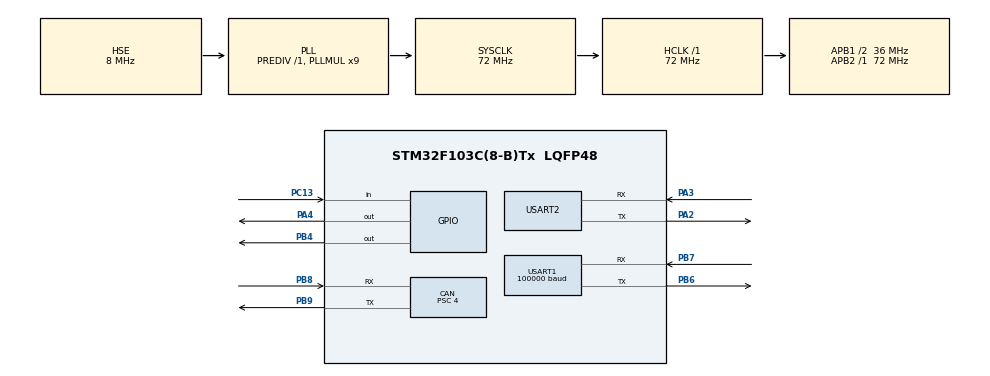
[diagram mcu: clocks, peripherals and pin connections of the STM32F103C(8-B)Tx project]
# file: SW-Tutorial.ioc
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CAN.BS1=CAN_BS1_6TQ
CAN.BS2=CAN_BS2_2TQ
CAN.CalculateBaudRate=1000000
CAN.CalculateTimeBit=1000
CAN.CalculateTimeQuantum=111.11111111111111
CAN.Mode=CAN_MODE_NORMAL
CAN.Prescaler=4
Dma.Request0=USART1_RX
Dma.USART1_RX.0.Direction=DMA_PERIPH_TO_MEMORY
Dma.USART1_RX.0.Instance=DMA1_Channel5
Dma.USART1_RX.0.MemDataAlignment=DMA_MDATAALIGN_BYTE
Dma.USART1_RX.0.MemInc=DMA_MINC_ENABLE
Dma.USART1_RX.0.Mode=DMA_NORMAL
Dma.USART1_RX.0.PeriphDataAlignment=DMA_PDATAALIGN_BYTE
Dma.USART1_RX.0.PeriphInc=DMA_PINC_DISABLE
Dma.USART1_RX.0.Priority=DMA_PRIORITY_VERY_HIGH
FREERTOS.Tasks01=defaultTask,24,128,StartDefaultTask,Default,NULL,Dynamic,NULL,NULL
Mcu.Family=STM32F1
Mcu.Name=STM32F103C(8-B)Tx
Mcu.Package=LQFP48
NVIC.DMA1_Channel5_IRQn=true\:5\:0\:false\:false\:true\:true\:false\:true\:true
NVIC.PriorityGroup=NVIC_PRIORITYGROUP_4
NVIC.TIM1_UP_IRQn=true\:15\:0\:false\:false\:true\:false\:false\:true\:true
NVIC.TimeBase=TIM1_UP_IRQn
NVIC.TimeBaseIP=TIM1
PA13.Mode=Serial_Wire
PA13.Signal=SYS_JTMS-SWDIO
PA14.Mode=Serial_Wire
PA14.Signal=SYS_JTCK-SWCLK
PA2.Mode=Asynchronous
PA2.Signal=USART2_TX
PA3.Mode=Asynchronous
PA3.Signal=USART2_RX
PA4.Signal=GPIO_Output
PB4.Signal=GPIO_Output
PB6.Mode=Asynchronous
PB6.Signal=USART1_TX
PB7.Mode=Asynchronous
PB7.Signal=USART1_RX
PB8.GPIO_PuPd=GPIO_PULLUP
PB8.Mode=CAN_Activate
PB8.Signal=CAN_RX
PB9.Mode=CAN_Activate
PB9.Signal=CAN_TX
PC13-TAMPER-RTC.Signal=GPIO_Input
PD0-OSC_IN.Mode=HSE-External-Oscillator
PD0-OSC_IN.Signal=RCC_OSC_IN
PD1-OSC_OUT.Mode=HSE-External-Oscillator
PD1-OSC_OUT.Signal=RCC_OSC_OUT
ProjectManager.HeapSize=0x200
ProjectManager.StackSize=0x400
ProjectManager.TargetToolchain=Makefile
RCC.AHBFreq_Value=72000000
RCC.APB1CLKDivider=RCC_HCLK_DIV2
RCC.APB1Freq_Value=36000000
RCC.APB1TimFreq_Value=72000000
RCC.APB2Freq_Value=72000000
RCC.APB2TimFreq_Value=72000000
RCC.HCLKFreq_Value=72000000
RCC.PLLMUL=RCC_PLL_MUL9
RCC.PLLSourceVirtual=RCC_PLLSOURCE_HSE
RCC.SYSCLKFreq_VALUE=72000000
RCC.SYSCLKSource=RCC_SYSCLKSOURCE_PLLCLK
RCC.USBFreq_Value=72000000
USART1.BaudRate=100000
USART1.Mode=MODE_RX
USART1.Parity=PARITY_EVEN
USART1.VirtualMode=VM_ASYNC
USART1.WordLength=WORDLENGTH_9B
USART2.Parity=PARITY_EVEN
USART2.VirtualMode=VM_ASYNC
USART2.WordLength=WORDLENGTH_9B
VP_FREERTOS_VS_CMSIS_V2.Mode=CMSIS_V2
VP_SYS_VS_tim1.Mode=TIM1
board=custom

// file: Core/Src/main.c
/* USER CODE BEGIN Header */
/**
 ******************************************************************************
 * @file           : main.c
 * @brief          : Main program body
 ******************************************************************************
 * @attention
 *
 * Copyright (c) 2022 STMicroelectronics.
 * All rights reserved.
 *
 * This software is licensed under terms that can be found in the LICENSE file
 * in the root directory of this software component.
 * If no LICENSE file comes with this software, it is provided AS-IS.
 *
 ******************************************************************************
 */
/* USER CODE END Header */
#include "main.h"
#include "cmsis_os.h"
#include "can.h"
#include "dma.h"
#include "usart.h"
#include "gpio.h"

/* USER CODE BEGIN Includes */
// #include "DR16.h"
#include "Motor.h"
/* USER CODE END Includes */

void SystemClock_Config(void);
void MX_FREERTOS_Init(void);

/* USER CODE BEGIN 0 */
extern void startUserTask();
/* USER CODE END 0 */

int main(void)
{

  /* MCU Configuration--------------------------------------------------------*/

  /* Reset of all peripherals, Initializes the Flash interface and the Systick. */
  HAL_Init();

  /* Configure the system clock */
  SystemClock_Config();

  /* Initialize all configured peripherals */
  MX_GPIO_Init();
  MX_DMA_Init();
  MX_CAN_Init();
  MX_USART1_UART_Init();
  MX_USART2_UART_Init();

  /* Init scheduler */
  osKernelInitialize();  /* Call init function for freertos objects (in freertos.c) */
  MX_FREERTOS_Init();

  /* Start scheduler */
  osKernelStart();

  /* We should never get here as control is now taken by the scheduler */
  /* Infinite loop */
  while (1)
  {

  }
}

void SystemClock_Config(void)
{
  RCC_OscInitTypeDef RCC_OscInitStruct = {0};
  RCC_ClkInitTypeDef RCC_ClkInitStruct = {0};

  /** Initializes the RCC Oscillators according to the specified parameters
  * in the RCC_OscInitTypeDef structure.
  */
  RCC_OscInitStruct.OscillatorType = RCC_OSCILLATORTYPE_HSE;
  RCC_OscInitStruct.HSEState = RCC_HSE_ON;
  RCC_OscInitStruct.HSEPredivValue = RCC_HSE_PREDIV_DIV1;
  RCC_OscInitStruct.HSIState = RCC_HSI_ON;
  RCC_OscInitStruct.PLL.PLLState = RCC_PLL_ON;
  RCC_OscInitStruct.PLL.PLLSource = RCC_PLLSOURCE_HSE;
  RCC_OscInitStruct.PLL.PLLMUL = RCC_PLL_MUL9;
  if (HAL_RCC_OscConfig(&RCC_OscInitStruct) != HAL_OK)
  {
    Error_Handler();
  }

  /** Initializes the CPU, AHB and APB buses clocks
  */
  RCC_ClkInitStruct.ClockType = RCC_CLOCKTYPE_HCLK|RCC_CLOCKTYPE_SYSCLK
                              |RCC_CLOCKTYPE_PCLK1|RCC_CLOCKTYPE_PCLK2;
  RCC_ClkInitStruct.SYSCLKSource = RCC_SYSCLKSOURCE_PLLCLK;
  RCC_ClkInitStruct.AHBCLKDivider = RCC_SYSCLK_DIV1;
  RCC_ClkInitStruct.APB1CLKDivider = RCC_HCLK_DIV2;
  RCC_ClkInitStruct.APB2CLKDivider = RCC_HCLK_DIV1;

  if (HAL_RCC_ClockConfig(&RCC_ClkInitStruct, FLASH_LATENCY_2) != HAL_OK)
  {
    Error_Handler();
  }
}

void HAL_TIM_PeriodElapsedCallback(TIM_HandleTypeDef *htim)
{
  if (htim->Instance == TIM1) {
    HAL_IncTick();
  }
}

void Error_Handler(void)
{
  __disable_irq();
  while (1)
  {
  }
}
